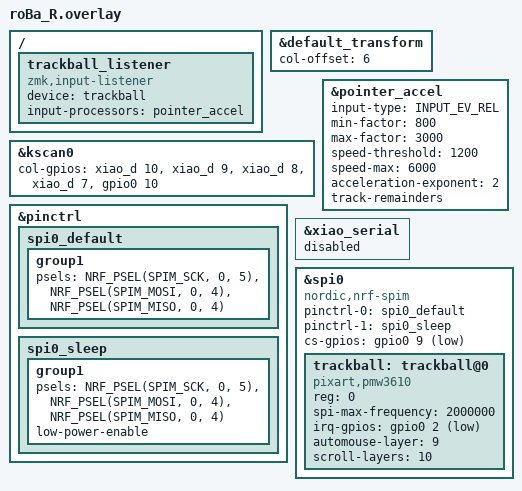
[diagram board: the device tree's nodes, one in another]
#include "roBa.dtsi"
#include <input/processors.dtsi>
#include <behaviors/input_gestures_accel.dtsi>
#include <zephyr/dt-bindings/input/input-event-codes.h>

&default_transform {
    col-offset = <6>;
};

&kscan0 {
        col-gpios
            = <&xiao_d 10 GPIO_ACTIVE_HIGH>
            , <&xiao_d 9 GPIO_ACTIVE_HIGH> 
            , <&xiao_d 8 GPIO_ACTIVE_HIGH> 
            , <&xiao_d 7 GPIO_ACTIVE_HIGH> 
            , <&gpio0 10 GPIO_ACTIVE_HIGH>
            ;
};

/ {
    trackball_listener {
        status = "okay";
        compatible = "zmk,input-listener";
        device = <&trackball>;
        input-processors = <&pointer_accel>;
    };
};

&pointer_accel {
    input-type = <INPUT_EV_REL>;
    min-factor = <800>;            // 遅い時 0.8倍（精密）
    max-factor = <3000>;           // 速い時 3.0倍（大移動）
    speed-threshold = <1200>;      // 加速が効き始める速度
    speed-max = <6000>;            // 最大加速に達する速度
    acceleration-exponent = <2>;   // カーブの効き（2=二次）
    track-remainders;
};

&pinctrl {
    spi0_default: spi0_default {
        group1 {
            psels = <NRF_PSEL(SPIM_SCK, 0, 5)>,
                <NRF_PSEL(SPIM_MOSI, 0, 4)>,
                <NRF_PSEL(SPIM_MISO, 0, 4)>;
        };
    };

    spi0_sleep: spi0_sleep {
        group1 {
            psels = <NRF_PSEL(SPIM_SCK, 0, 5)>,
                <NRF_PSEL(SPIM_MOSI, 0, 4)>,
                <NRF_PSEL(SPIM_MISO, 0, 4)>;
            low-power-enable;
        };
    };
};

&xiao_serial { status = "disabled"; };

&spi0 {
    status = "okay";
    compatible = "nordic,nrf-spim";
    pinctrl-0 = <&spi0_default>;
    pinctrl-1 = <&spi0_sleep>;
    pinctrl-names = "default", "sleep";
    cs-gpios = <&gpio0 9 GPIO_ACTIVE_LOW>;

    trackball: trackball@0 {
        status = "okay";
        compatible = "pixart,pmw3610";
        reg = <0>;
        spi-max-frequency = <2000000>;
        irq-gpios = <&gpio0 2 (GPIO_ACTIVE_LOW | GPIO_PULL_UP)>;
        automouse-layer = <9>;
        scroll-layers = <10>;
    };
};


